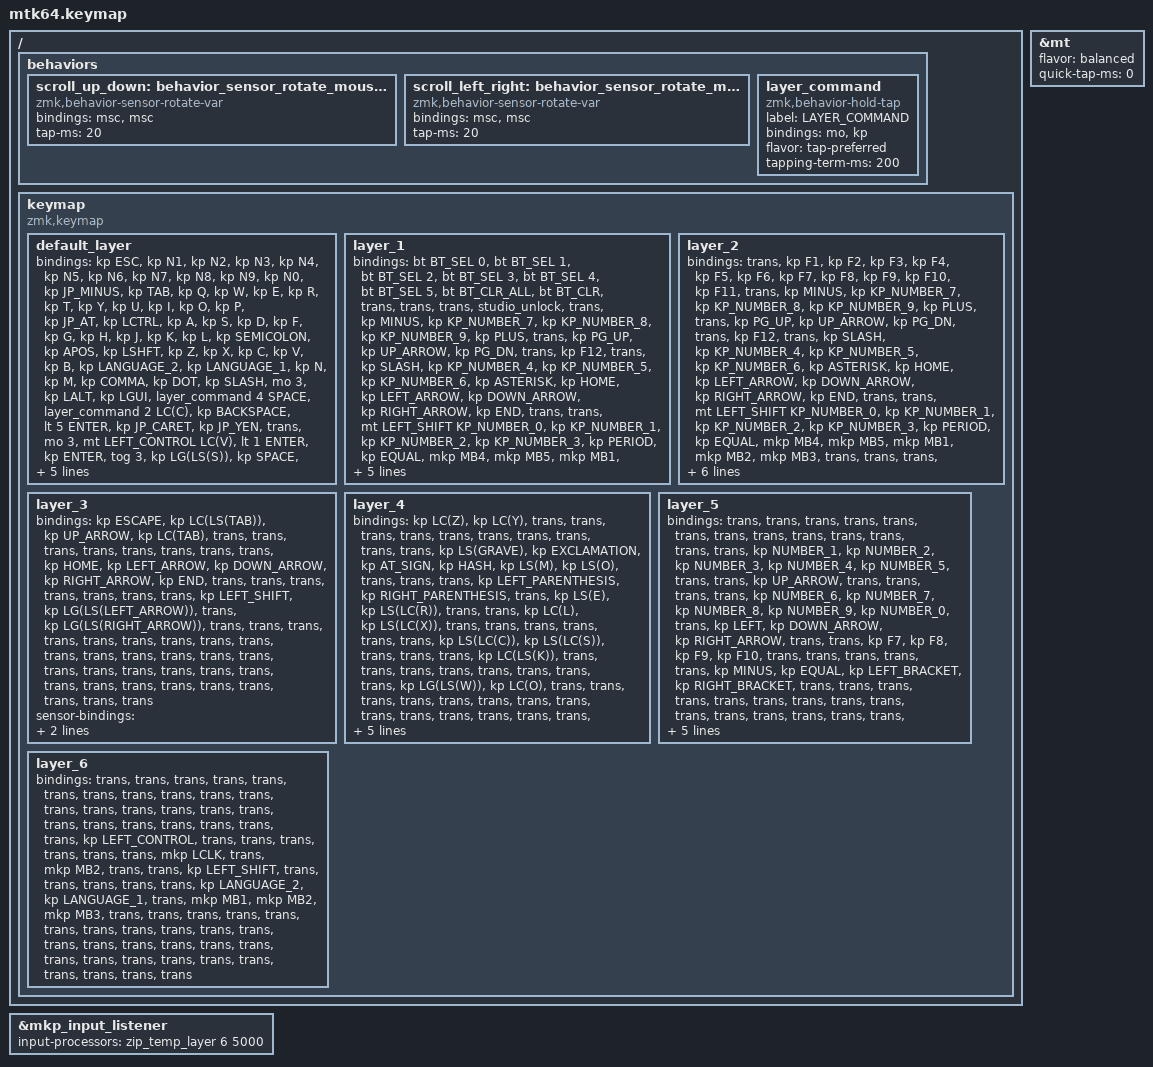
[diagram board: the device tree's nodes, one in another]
#include <input/processors.dtsi>
#include <behaviors.dtsi>
#include <dt-bindings/zmk/bt.h>
#include <dt-bindings/zmk/keys.h>
#include <dt-bindings/zmk/pointing.h>
#include "keycode_japanese.h"

// スクロール量の設定

#define ZMK_POINTING_DEFAULT_SCRL_VAL 100

&mt {
    flavor = "balanced";
    quick-tap-ms = <0>;
};

&mkp_input_listener { input-processors = <&zip_temp_layer 6 5000>; };

/ {
    behaviors {
        // 垂直スクロール用のbehaviorの設定

        scroll_up_down: behavior_sensor_rotate_mouse_wheel_up_down {
            compatible = "zmk,behavior-sensor-rotate-var";
            #sensor-binding-cells = <2>;
            bindings = <&msc>, <&msc>;

            tap-ms = <20>; // スクロールのタップ時間
        };

        // 水平スクロール用のbehaviorの設定

        scroll_left_right: behavior_sensor_rotate_mouse_wheel_left_right {
            compatible = "zmk,behavior-sensor-rotate-var";
            #sensor-binding-cells = <2>;
            bindings = <&msc>, <&msc>;

            tap-ms = <20>; // スクロールのタップ時間
        };

        layer_command: layer_command {
            compatible = "zmk,behavior-hold-tap";
            label = "LAYER_COMMAND";
            bindings = <&mo>, <&kp>;

            #binding-cells = <2>;
            flavor = "tap-preferred";
            tapping-term-ms = <200>;
        };
    };
};

/ {
    keymap {
        compatible = "zmk,keymap";

        default_layer {
            bindings = <
&kp ESC  &kp N1  &kp N2  &kp N3  &kp N4  &kp N5  &kp N6  &kp N7  &kp N8  &kp N9  &kp N0  &kp JP_MINUS  &kp TAB  &kp Q  &kp W  &kp E  &kp R  &kp T  &kp Y  &kp U  &kp I  &kp O  &kp P  &kp JP_AT  &kp LCTRL  &kp A  &kp S  &kp D  &kp F  &kp G  &kp H  &kp J  &kp K  &kp L  &kp SEMICOLON  &kp APOS  &kp LSHFT  &kp Z  &kp X  &kp C  &kp V  &kp B  &kp LANGUAGE_2  &kp LANGUAGE_1  &kp N  &kp M  &kp COMMA  &kp DOT  &kp SLASH  &mo 3  &kp LALT  &kp LGUI  &layer_command 4 SPACE  &layer_command 2 LC(C)  &kp BACKSPACE  &lt 5 ENTER  &kp JP_CARET  &kp JP_YEN  &trans  &mo 3  &mt LEFT_CONTROL LC(V)  &lt 1 ENTER  &kp ENTER  &tog 3  &kp LG(LS(S))  &kp SPACE  &mo 2  &mo 3  &mo 4  &mo 2  &mo 3  &mo 4  &mo 2  &mo 3  &mo 4
            >;

            sensor-bindings =
                <&scroll_left_right SCRL_LEFT SCRL_RIGHT>,
                <&scroll_up_down SCRL_UP SCRL_DOWN>;
        };

        layer_1 {
            bindings = <
&bt BT_SEL 0  &bt BT_SEL 1  &bt BT_SEL 2  &bt BT_SEL 3  &bt BT_SEL 4  &bt BT_SEL 5  &bt BT_CLR_ALL  &bt BT_CLR  &trans  &trans  &trans  &studio_unlock  &trans  &kp MINUS  &kp KP_NUMBER_7  &kp KP_NUMBER_8  &kp KP_NUMBER_9  &kp PLUS  &trans  &kp PG_UP  &kp UP_ARROW  &kp PG_DN  &trans  &kp F12  &trans  &kp SLASH  &kp KP_NUMBER_4  &kp KP_NUMBER_5  &kp KP_NUMBER_6  &kp ASTERISK  &kp HOME  &kp LEFT_ARROW  &kp DOWN_ARROW  &kp RIGHT_ARROW  &kp END  &trans  &trans  &mt LEFT_SHIFT KP_NUMBER_0  &kp KP_NUMBER_1  &kp KP_NUMBER_2  &kp KP_NUMBER_3  &kp PERIOD  &kp EQUAL  &mkp MB4  &mkp MB5  &mkp MB1  &mkp MB2  &mkp MB3  &trans  &trans  &trans  &trans  &trans  &trans  &trans  &trans  &trans  &trans  &trans  &trans  &trans  &trans  &trans  &trans  &trans  &trans  &trans  &trans  &trans  &trans  &trans  &trans  &trans  &trans  &trans
            >;
        };

        layer_2 {
            bindings = <
&trans  &kp F1  &kp F2  &kp F3  &kp F4  &kp F5  &kp F6  &kp F7  &kp F8  &kp F9  &kp F10  &kp F11  &trans  &kp MINUS  &kp KP_NUMBER_7  &kp KP_NUMBER_8  &kp KP_NUMBER_9  &kp PLUS  &trans  &kp PG_UP  &kp UP_ARROW  &kp PG_DN  &trans  &kp F12  &trans  &kp SLASH  &kp KP_NUMBER_4  &kp KP_NUMBER_5  &kp KP_NUMBER_6  &kp ASTERISK  &kp HOME  &kp LEFT_ARROW  &kp DOWN_ARROW  &kp RIGHT_ARROW  &kp END  &trans  &trans  &mt LEFT_SHIFT KP_NUMBER_0  &kp KP_NUMBER_1  &kp KP_NUMBER_2  &kp KP_NUMBER_3  &kp PERIOD  &kp EQUAL  &mkp MB4  &mkp MB5  &mkp MB1  &mkp MB2  &mkp MB3  &trans  &trans  &trans  &trans  &trans  &trans  &trans  &trans  &trans  &trans  &trans  &mo 3  &trans  &trans  &trans  &trans  &trans  &trans  &trans  &trans  &trans  &trans  &trans  &trans  &trans  &trans  &trans
            >;

            sensor-bindings =
                <&inc_dec_kp TAB LS(TAB)>,
                <&scroll_up_down SCRL_UP SCRL_DOWN>;
        };

        layer_3 {
            bindings = <
&kp ESCAPE  &kp LC(LS(TAB))  &kp UP_ARROW  &kp LC(TAB)  &trans  &trans  &trans  &trans  &trans  &trans  &trans  &trans  &kp HOME  &kp LEFT_ARROW  &kp DOWN_ARROW  &kp RIGHT_ARROW  &kp END  &trans  &trans  &trans  &trans  &trans  &trans  &trans  &kp LEFT_SHIFT  &kp LG(LS(LEFT_ARROW))  &trans  &kp LG(LS(RIGHT_ARROW))  &trans  &trans  &trans  &trans  &trans  &trans  &trans  &trans  &trans  &trans  &trans  &trans  &trans  &trans  &trans  &trans  &trans  &trans  &trans  &trans  &trans  &trans  &trans  &trans  &trans  &trans  &trans  &trans  &trans  &trans
            >;

            sensor-bindings =
                <&scroll_left_right SCRL_LEFT SCRL_RIGHT>,
                <&inc_dec_kp PG_UP PG_DN>;
        };

        layer_4 {
            bindings = <
&kp LC(Z)  &kp LC(Y)  &trans  &trans  &trans  &trans  &trans  &trans  &trans  &trans  &trans  &trans  &kp LS(GRAVE)  &kp EXCLAMATION  &kp AT_SIGN  &kp HASH  &kp LS(M)  &kp LS(O)  &trans  &trans  &trans  &kp LEFT_PARENTHESIS  &kp RIGHT_PARENTHESIS  &trans  &kp LS(E)  &kp LS(LC(R))  &trans  &trans  &kp LC(L)  &kp LS(LC(X))  &trans  &trans  &trans  &trans  &trans  &trans  &kp LS(LC(C))  &kp LS(LC(S))  &trans  &trans  &trans  &kp LC(LS(K))  &trans  &trans  &trans  &trans  &trans  &trans  &trans  &trans  &kp LG(LS(W))  &kp LC(O)  &trans  &trans  &trans  &trans  &trans  &trans  &trans  &trans  &trans  &trans  &trans  &trans  &trans  &trans  &trans  &trans  &trans  &trans  &trans  &trans  &trans  &trans  &trans
            >;

            sensor-bindings =
                <&inc_dec_kp C_VOLUME_DOWN C_VOLUME_UP>,
                <&inc_dec_kp J L>;
        };

        layer_5 {
            bindings = <
&trans  &trans  &trans  &trans  &trans  &trans  &trans  &trans  &trans  &trans  &trans  &trans  &trans  &kp NUMBER_1  &kp NUMBER_2  &kp NUMBER_3  &kp NUMBER_4  &kp NUMBER_5  &trans  &trans  &kp UP_ARROW  &trans  &trans  &trans  &trans  &kp NUMBER_6  &kp NUMBER_7  &kp NUMBER_8  &kp NUMBER_9  &kp NUMBER_0  &trans  &kp LEFT  &kp DOWN_ARROW  &kp RIGHT_ARROW  &trans  &trans  &kp F7  &kp F8  &kp F9  &kp F10  &trans  &trans  &trans  &trans  &trans  &kp MINUS  &kp EQUAL  &kp LEFT_BRACKET  &kp RIGHT_BRACKET  &trans  &trans  &trans  &trans  &trans  &trans  &trans  &trans  &trans  &trans  &trans  &trans  &trans  &trans  &trans  &trans  &trans  &trans  &trans  &trans  &trans  &trans  &trans  &trans  &trans  &trans
            >;

            sensor-bindings =
                <&inc_dec_kp LEFT_ARROW RIGHT_ARROW>,
                <&inc_dec_kp UP_ARROW DOWN_ARROW>;
        };

        layer_6 {
            bindings = <
&trans  &trans  &trans  &trans  &trans  &trans  &trans  &trans  &trans  &trans  &trans  &trans  &trans  &trans  &trans  &trans  &trans  &trans  &trans  &trans  &trans  &trans  &trans  &trans  &kp LEFT_CONTROL  &trans  &trans  &trans  &trans  &trans  &trans  &mkp LCLK  &trans  &mkp MB2  &trans  &trans  &kp LEFT_SHIFT  &trans  &trans  &trans  &trans  &trans  &kp LANGUAGE_2  &kp LANGUAGE_1  &trans  &mkp MB1  &mkp MB2  &mkp MB3  &trans  &trans  &trans  &trans  &trans  &trans  &trans  &trans  &trans  &trans  &trans  &trans  &trans  &trans  &trans  &trans  &trans  &trans  &trans  &trans  &trans  &trans  &trans  &trans  &trans  &trans  &trans
            >;
        };
    };
};
